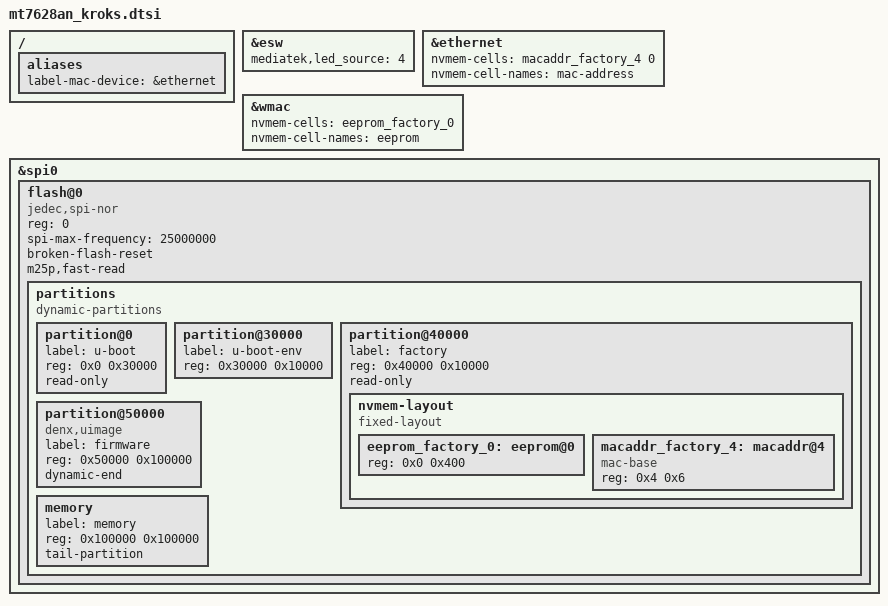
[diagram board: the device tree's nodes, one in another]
#include "mt7628an.dtsi"

/ {
	aliases {
		label-mac-device = &ethernet;
	};
};

&esw {
	mediatek,led_source = <4>;
};

&ethernet {
	nvmem-cells = <&macaddr_factory_4 0>;
	nvmem-cell-names = "mac-address";
};

&wmac {
	status = "okay";

	nvmem-cells = <&eeprom_factory_0>;
	nvmem-cell-names = "eeprom";
};

&spi0 {
	status = "okay";

	/* Winbond W25Q128JV */
	flash@0 {
		compatible = "jedec,spi-nor";
		reg = <0>;
		spi-max-frequency = <25000000>;
		broken-flash-reset;
		m25p,fast-read;

		partitions {
			compatible = "dynamic-partitions";
			#address-cells = <1>;
			#size-cells = <1>;

			partition@0 {
				label = "u-boot";
				reg = <0x0 0x30000>;
				read-only;
			};

			partition@30000 {
				label = "u-boot-env";
				reg = <0x30000 0x10000>;
			};

			partition@40000 {
				label = "factory";
				reg = <0x40000 0x10000>;
				read-only;

				nvmem-layout {
					compatible = "fixed-layout";
					#address-cells = <1>;
					#size-cells = <1>;

					eeprom_factory_0: eeprom@0 {
						reg = <0x0 0x400>;
					};

					macaddr_factory_4: macaddr@4 {
						compatible = "mac-base";
						reg = <0x4 0x6>;
						#nvmem-cell-cells = <1>;
					};
				};
			};

			partition@50000 {
				compatible = "denx,uimage";
				label = "firmware";
				reg = <0x50000 0x100000>;
				dynamic-end;
			};

			memory {
				label = "memory";
				reg = <0x100000 0x100000>;
				tail-partition;
			};
		};
	};
};
